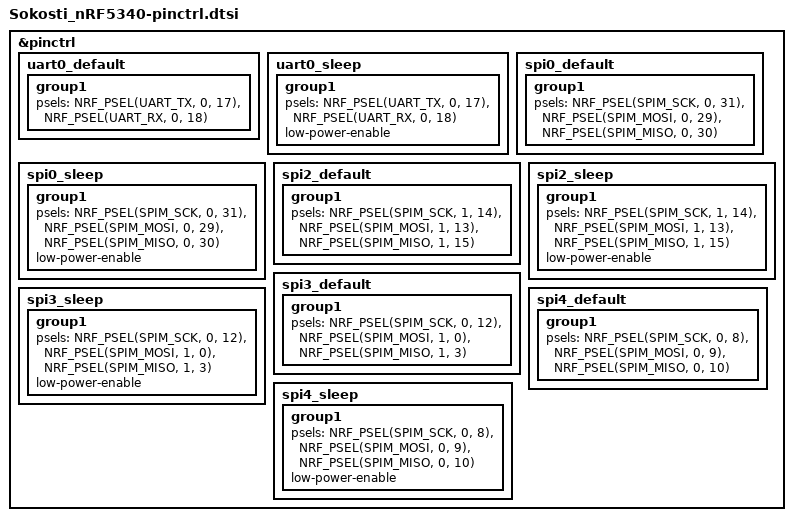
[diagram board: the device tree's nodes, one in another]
&pinctrl {
	/* UART0 pin configuration */
	uart0_default: uart0_default {
		group1 {
			psels = <NRF_PSEL(UART_TX, 0, 17)>,
					<NRF_PSEL(UART_RX, 0, 18)>;
		};
	};

	uart0_sleep: uart0_sleep {
		group1 {
			psels = <NRF_PSEL(UART_TX, 0, 17)>,
					<NRF_PSEL(UART_RX, 0, 18)>;
			low-power-enable;
		};
	};

	/* SPI0 pin configuration (microSD card) */
	spi0_default: spi0_default {
		group1 {
			psels = <NRF_PSEL(SPIM_SCK, 0, 31)>,
					<NRF_PSEL(SPIM_MOSI, 0, 29)>,
					<NRF_PSEL(SPIM_MISO, 0, 30)>;
		};
	};

	spi0_sleep: spi0_sleep {
		group1 {
			psels = <NRF_PSEL(SPIM_SCK, 0, 31)>,
					<NRF_PSEL(SPIM_MOSI, 0, 29)>,
					<NRF_PSEL(SPIM_MISO, 0, 30)>;
			low-power-enable;
		};
	};

	/* SPI2 pin configuration (Main IMU) */
	spi2_default: spi2_default {
		group1 {
			psels = <NRF_PSEL(SPIM_SCK, 1, 14)>,
					<NRF_PSEL(SPIM_MOSI, 1, 13)>,
					<NRF_PSEL(SPIM_MISO, 1, 15)>;
		};
	};

	spi2_sleep: spi2_sleep {
		group1 {
			psels = <NRF_PSEL(SPIM_SCK, 1, 14)>,
					<NRF_PSEL(SPIM_MOSI, 1, 13)>,
					<NRF_PSEL(SPIM_MISO, 1, 15)>;
			low-power-enable;
		};
	};

	/* SPI3 pin configuration (External IMU) */
	spi3_default: spi3_default {
		group1 {
			psels = <NRF_PSEL(SPIM_SCK, 0, 12)>,
					<NRF_PSEL(SPIM_MOSI, 1, 0)>,
					<NRF_PSEL(SPIM_MISO, 1, 3)>;
		};
	};

	spi3_sleep: spi3_sleep {
		group1 {
			psels = <NRF_PSEL(SPIM_SCK, 0, 12)>,
					<NRF_PSEL(SPIM_MOSI, 1, 0)>,
					<NRF_PSEL(SPIM_MISO, 1, 3)>;
			low-power-enable;
		};
	};

	/* SPI4 pin configuration (ADS1299 ADC) */
	spi4_default: spi4_default {
		group1 {
			psels = <NRF_PSEL(SPIM_SCK, 0, 8)>,
					<NRF_PSEL(SPIM_MOSI, 0, 9)>,
					<NRF_PSEL(SPIM_MISO, 0, 10)>;
		};
	};

	spi4_sleep: spi4_sleep {
		group1 {
			psels = <NRF_PSEL(SPIM_SCK, 0, 8)>,
					<NRF_PSEL(SPIM_MOSI, 0, 9)>,
					<NRF_PSEL(SPIM_MISO, 0, 10)>;
			low-power-enable;
		};
	};
};
